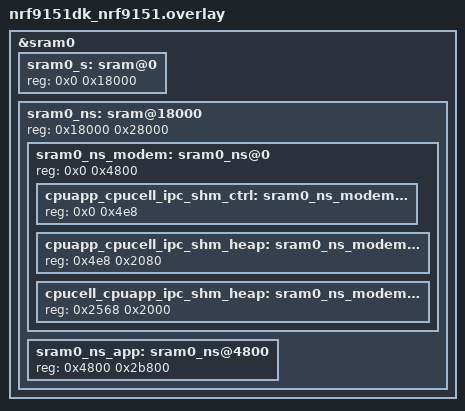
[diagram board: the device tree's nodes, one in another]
/*
 * Copyright (c) 2026 Nordic Semiconductor ASA
 *
 * SPDX-License-Identifier: LicenseRef-Nordic-5-Clause
 */

/delete-node/ &sram0_s;
/delete-node/ &sram0_ns;

&sram0 {
	sram0_s: sram@0 {
		/* Secure image memory. Increase to 96 kB for this test. */
		reg = <0x0 0x18000>;
	};

	sram0_ns: sram@18000 {
		/* Non-Secure image memory */
		reg = <0x18000 0x28000>;
		#address-cells = <1>;
		#size-cells = <1>;
		ranges = <0x0 0x10000 0x28000>;

		sram0_ns_modem: sram0_ns@0 {
			/* Modem (shared) memory */
			reg = <0x0 0x4800>;
			#address-cells = <1>;
			#size-cells = <1>;
			ranges = <0x0 0x0 0x4800>;

			cpuapp_cpucell_ipc_shm_ctrl: sram0_ns_modem@0 {
				/* Modem IPC control */
				reg = <0x0 0x4e8>;
			};

			cpuapp_cpucell_ipc_shm_heap: sram0_ns_modem@4e8 {
				/* Modem IPC transmit */
				reg = <0x4e8 0x2080>;
			};

			cpucell_cpuapp_ipc_shm_heap: sram0_ns_modem@2568 {
				/* Modem IPC receive */
				reg = <0x2568 0x2000>;
			};
		};

		sram0_ns_app: sram0_ns@4800 {
			/* Non-Secure application memory */
			reg = <0x4800 0x2b800>;
		};
	};
};
